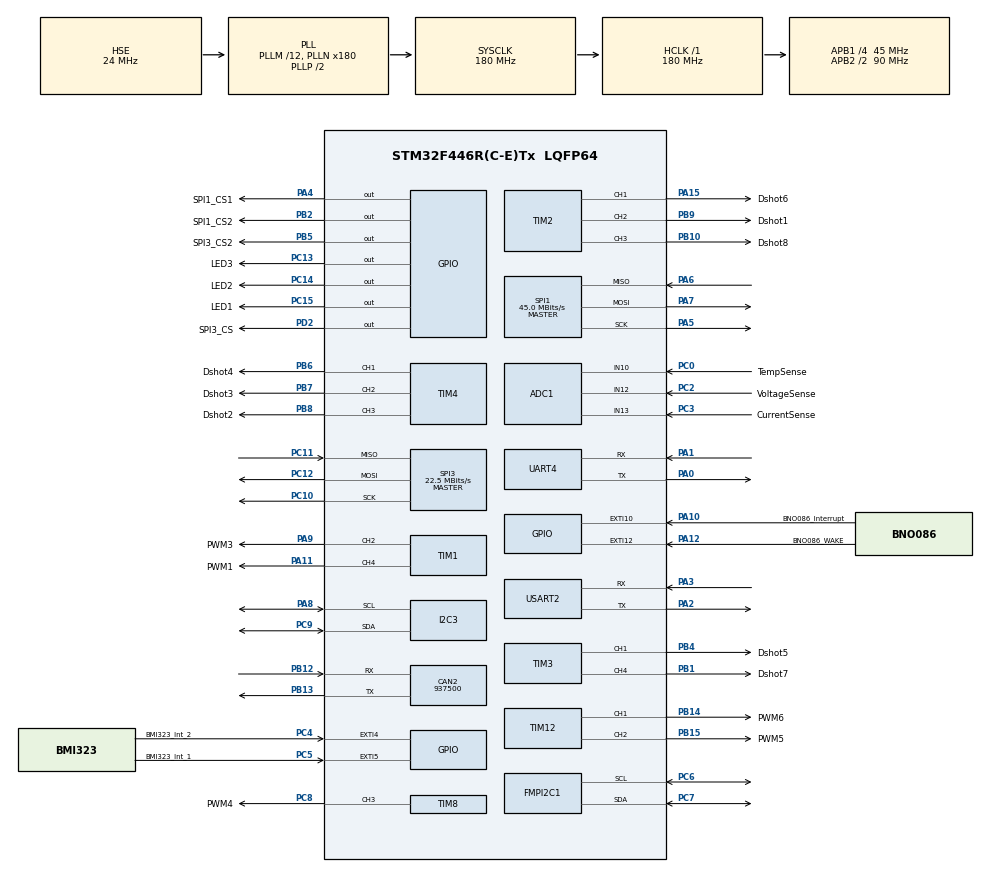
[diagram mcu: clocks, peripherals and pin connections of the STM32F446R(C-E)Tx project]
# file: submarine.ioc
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ADC1.Channel-0\#ChannelRegularConversion=ADC_CHANNEL_13
ADC1.Channel-1\#ChannelRegularConversion=ADC_CHANNEL_12
ADC1.Channel-2\#ChannelRegularConversion=ADC_CHANNEL_10
ADC1.ContinuousConvMode=ENABLE
ADC1.DMAContinuousRequests=ENABLE
ADC1.NbrOfConversion=3
ADC1.NbrOfConversionFlag=1
ADC1.Rank-0\#ChannelRegularConversion=1
ADC1.Rank-1\#ChannelRegularConversion=2
ADC1.Rank-2\#ChannelRegularConversion=3
ADC1.SamplingTime-0\#ChannelRegularConversion=ADC_SAMPLETIME_112CYCLES
ADC1.SamplingTime-1\#ChannelRegularConversion=ADC_SAMPLETIME_112CYCLES
ADC1.SamplingTime-2\#ChannelRegularConversion=ADC_SAMPLETIME_112CYCLES
ADC1.master=1
CAN2.BS1=CAN_BS1_1TQ
CAN2.BS2=CAN_BS2_1TQ
CAN2.CalculateBaudRate=937500
CAN2.CalculateTimeBit=1066
CAN2.CalculateTimeQuantum=355.55555555555554
Dma.ADC1.8.Direction=DMA_PERIPH_TO_MEMORY
Dma.ADC1.8.FIFOMode=DMA_FIFOMODE_DISABLE
Dma.ADC1.8.Instance=DMA2_Stream0
Dma.ADC1.8.MemDataAlignment=DMA_MDATAALIGN_HALFWORD
Dma.ADC1.8.MemInc=DMA_MINC_ENABLE
Dma.ADC1.8.Mode=DMA_CIRCULAR
Dma.ADC1.8.PeriphDataAlignment=DMA_PDATAALIGN_HALFWORD
Dma.ADC1.8.PeriphInc=DMA_PINC_DISABLE
Dma.ADC1.8.Priority=DMA_PRIORITY_LOW
Dma.Request0=TIM4_CH2
Dma.Request1=TIM2_CH1
Dma.Request2=TIM2_CH2/CH4
Dma.Request3=TIM3_CH1/TRIG
Dma.Request4=TIM3_CH4/UP
Dma.Request5=TIM2_UP/CH3
Dma.Request6=TIM4_CH3
Dma.Request7=TIM4_CH1
Dma.Request8=ADC1
Dma.TIM2_CH1.1.Direction=DMA_PERIPH_TO_MEMORY
Dma.TIM2_CH1.1.FIFOMode=DMA_FIFOMODE_DISABLE
Dma.TIM2_CH1.1.Instance=DMA1_Stream5
Dma.TIM2_CH1.1.MemDataAlignment=DMA_MDATAALIGN_WORD
Dma.TIM2_CH1.1.MemInc=DMA_MINC_ENABLE
Dma.TIM2_CH1.1.Mode=DMA_NORMAL
Dma.TIM2_CH1.1.PeriphDataAlignment=DMA_PDATAALIGN_WORD
Dma.TIM2_CH1.1.PeriphInc=DMA_PINC_DISABLE
Dma.TIM2_CH1.1.Priority=DMA_PRIORITY_LOW
Dma.TIM2_CH2/CH4.2.Direction=DMA_PERIPH_TO_MEMORY
Dma.TIM2_CH2/CH4.2.FIFOMode=DMA_FIFOMODE_DISABLE
Dma.TIM2_CH2/CH4.2.Instance=DMA1_Stream6
Dma.TIM2_CH2/CH4.2.MemDataAlignment=DMA_MDATAALIGN_WORD
Dma.TIM2_CH2/CH4.2.MemInc=DMA_MINC_ENABLE
Dma.TIM2_CH2/CH4.2.Mode=DMA_NORMAL
Dma.TIM2_CH2/CH4.2.PeriphDataAlignment=DMA_PDATAALIGN_WORD
Dma.TIM2_CH2/CH4.2.PeriphInc=DMA_PINC_DISABLE
Dma.TIM2_CH2/CH4.2.Priority=DMA_PRIORITY_LOW
Dma.TIM2_UP/CH3.5.Direction=DMA_PERIPH_TO_MEMORY
Dma.TIM2_UP/CH3.5.FIFOMode=DMA_FIFOMODE_DISABLE
Dma.TIM2_UP/CH3.5.Instance=DMA1_Stream1
Dma.TIM2_UP/CH3.5.MemDataAlignment=DMA_MDATAALIGN_WORD
Dma.TIM2_UP/CH3.5.MemInc=DMA_MINC_ENABLE
Dma.TIM2_UP/CH3.5.Mode=DMA_NORMAL
Dma.TIM2_UP/CH3.5.PeriphDataAlignment=DMA_PDATAALIGN_WORD
Dma.TIM2_UP/CH3.5.PeriphInc=DMA_PINC_DISABLE
Dma.TIM2_UP/CH3.5.Priority=DMA_PRIORITY_LOW
Dma.TIM3_CH1/TRIG.3.Direction=DMA_PERIPH_TO_MEMORY
Dma.TIM3_CH1/TRIG.3.FIFOMode=DMA_FIFOMODE_DISABLE
Dma.TIM3_CH1/TRIG.3.Instance=DMA1_Stream4
Dma.TIM3_CH1/TRIG.3.MemDataAlignment=DMA_MDATAALIGN_HALFWORD
Dma.TIM3_CH1/TRIG.3.MemInc=DMA_MINC_ENABLE
Dma.TIM3_CH1/TRIG.3.Mode=DMA_NORMAL
Dma.TIM3_CH1/TRIG.3.PeriphDataAlignment=DMA_PDATAALIGN_HALFWORD
Dma.TIM3_CH1/TRIG.3.PeriphInc=DMA_PINC_DISABLE
Dma.TIM3_CH1/TRIG.3.Priority=DMA_PRIORITY_LOW
Dma.TIM3_CH4/UP.4.Direction=DMA_PERIPH_TO_MEMORY
Dma.TIM3_CH4/UP.4.FIFOMode=DMA_FIFOMODE_DISABLE
Dma.TIM3_CH4/UP.4.Instance=DMA1_Stream2
Dma.TIM3_CH4/UP.4.MemDataAlignment=DMA_MDATAALIGN_HALFWORD
Dma.TIM3_CH4/UP.4.MemInc=DMA_MINC_ENABLE
Dma.TIM3_CH4/UP.4.Mode=DMA_NORMAL
Dma.TIM3_CH4/UP.4.PeriphDataAlignment=DMA_PDATAALIGN_HALFWORD
Dma.TIM3_CH4/UP.4.PeriphInc=DMA_PINC_DISABLE
Dma.TIM3_CH4/UP.4.Priority=DMA_PRIORITY_LOW
Dma.TIM4_CH1.7.Direction=DMA_PERIPH_TO_MEMORY
Dma.TIM4_CH1.7.FIFOMode=DMA_FIFOMODE_DISABLE
Dma.TIM4_CH1.7.Instance=DMA1_Stream0
Dma.TIM4_CH1.7.MemDataAlignment=DMA_MDATAALIGN_HALFWORD
Dma.TIM4_CH1.7.MemInc=DMA_MINC_ENABLE
Dma.TIM4_CH1.7.Mode=DMA_NORMAL
Dma.TIM4_CH1.7.PeriphDataAlignment=DMA_PDATAALIGN_HALFWORD
Dma.TIM4_CH1.7.PeriphInc=DMA_PINC_DISABLE
Dma.TIM4_CH1.7.Priority=DMA_PRIORITY_LOW
Dma.TIM4_CH2.0.Direction=DMA_PERIPH_TO_MEMORY
Dma.TIM4_CH2.0.FIFOMode=DMA_FIFOMODE_DISABLE
Dma.TIM4_CH2.0.Instance=DMA1_Stream3
Dma.TIM4_CH2.0.MemDataAlignment=DMA_MDATAALIGN_HALFWORD
Dma.TIM4_CH2.0.MemInc=DMA_MINC_ENABLE
Dma.TIM4_CH2.0.Mode=DMA_NORMAL
Dma.TIM4_CH2.0.PeriphDataAlignment=DMA_PDATAALIGN_HALFWORD
Dma.TIM4_CH2.0.PeriphInc=DMA_PINC_DISABLE
Dma.TIM4_CH2.0.Priority=DMA_PRIORITY_LOW
Dma.TIM4_CH3.6.Direction=DMA_PERIPH_TO_MEMORY
Dma.TIM4_CH3.6.FIFOMode=DMA_FIFOMODE_DISABLE
Dma.TIM4_CH3.6.Instance=DMA1_Stream7
Dma.TIM4_CH3.6.MemDataAlignment=DMA_MDATAALIGN_HALFWORD
Dma.TIM4_CH3.6.MemInc=DMA_MINC_ENABLE
Dma.TIM4_CH3.6.Mode=DMA_NORMAL
Dma.TIM4_CH3.6.PeriphDataAlignment=DMA_PDATAALIGN_HALFWORD
Dma.TIM4_CH3.6.PeriphInc=DMA_PINC_DISABLE
Dma.TIM4_CH3.6.Priority=DMA_PRIORITY_LOW
FMPI2C1.Timeout=0x00008225
FMPI2C1.Timing=0xC0000E12
Mcu.Family=STM32F4
Mcu.Name=STM32F446R(C-E)Tx
Mcu.Package=LQFP64
NVIC.ADC_IRQn=true\:0\:0\:false\:false\:true\:true\:true\:true
NVIC.DMA1_Stream0_IRQn=true\:0\:0\:false\:false\:true\:false\:true\:true
NVIC.DMA1_Stream1_IRQn=true\:0\:0\:false\:false\:true\:false\:true\:true
NVIC.DMA1_Stream2_IRQn=true\:0\:0\:false\:false\:true\:false\:true\:true
NVIC.DMA1_Stream3_IRQn=true\:0\:0\:false\:false\:true\:false\:true\:true
NVIC.DMA1_Stream4_IRQn=true\:0\:0\:false\:false\:true\:false\:true\:true
NVIC.DMA1_Stream5_IRQn=true\:0\:0\:false\:false\:true\:false\:true\:true
NVIC.DMA1_Stream6_IRQn=true\:0\:0\:false\:false\:true\:false\:true\:true
NVIC.DMA1_Stream7_IRQn=true\:0\:0\:false\:false\:true\:false\:true\:true
NVIC.DMA2_Stream0_IRQn=true\:0\:0\:false\:false\:true\:false\:true\:true
NVIC.PriorityGroup=NVIC_PRIORITYGROUP_4
PA0-WKUP.Mode=Asynchronous
PA0-WKUP.Signal=UART4_TX
PA1.Mode=Asynchronous
PA1.Signal=UART4_RX
PA10.GPIO_Label=BNO086_Interrupt
PA10.Signal=GPXTI10
PA11.GPIO_Label=PWM1
PA11.Signal=S_TIM1_CH4
PA12.GPIO_Label=BNO086_WAKE
PA12.Signal=GPXTI12
PA13.Mode=Trace_Asynchronous_SW
PA13.Signal=SYS_JTMS-SWDIO
PA14.Mode=Trace_Asynchronous_SW
PA14.Signal=SYS_JTCK-SWCLK
PA15.GPIO_Label=Dshot6
PA15.Signal=S_TIM2_CH1_ETR
PA2.Mode=Asynchronous
PA2.Signal=USART2_TX
PA3.Mode=Asynchronous
PA3.Signal=USART2_RX
PA4.GPIO_Label=SPI1_CS1
PA4.Signal=GPIO_Output
PA5.Mode=Full_Duplex_Master
PA5.Signal=SPI1_SCK
PA6.Mode=Full_Duplex_Master
PA6.Signal=SPI1_MISO
PA7.Mode=Full_Duplex_Master
PA7.Signal=SPI1_MOSI
PA8.Mode=I2C
PA8.Signal=I2C3_SCL
PA9.GPIO_Label=PWM3
PA9.Signal=S_TIM1_CH2
PB1.GPIO_Label=Dshot7
PB1.Signal=S_TIM3_CH4
PB10.GPIO_Label=Dshot8
PB10.Signal=S_TIM2_CH3
PB12.Mode=CAN_Activate
PB12.Signal=CAN2_RX
PB13.Mode=CAN_Activate
PB13.Signal=CAN2_TX
PB14.GPIO_Label=PWM6
PB14.Signal=S_TIM12_CH1
PB15.GPIO_Label=PWM5
PB15.Signal=S_TIM12_CH2
PB2.GPIO_Label=SPI1_CS2
PB2.Signal=GPIO_Output
PB3.Mode=Trace_Asynchronous_SW
PB3.Signal=SYS_JTDO-SWO
PB4.GPIO_Label=Dshot5
PB4.Signal=S_TIM3_CH1
PB5.GPIO_Label=SPI3_CS2
PB5.Signal=GPIO_Output
PB6.GPIO_Label=Dshot4
PB6.Signal=S_TIM4_CH1
PB7.GPIO_Label=Dshot3
PB7.Signal=S_TIM4_CH2
PB8.GPIO_Label=Dshot2
PB8.Signal=S_TIM4_CH3
PB9.GPIO_Label=Dshot1
PB9.Signal=S_TIM2_CH2
PC0.GPIO_Label=TempSense
PC0.Signal=ADCx_IN10
PC10.Mode=Full_Duplex_Master
PC10.Signal=SPI3_SCK
PC11.Mode=Full_Duplex_Master
PC11.Signal=SPI3_MISO
PC12.Mode=Full_Duplex_Master
PC12.Signal=SPI3_MOSI
PC13.GPIO_Label=LED3
PC13.PinState=GPIO_PIN_SET
PC13.Signal=GPIO_Output
PC14-OSC32_IN.GPIO_Label=LED2
PC14-OSC32_IN.PinState=GPIO_PIN_SET
PC14-OSC32_IN.Signal=GPIO_Output
PC15-OSC32_OUT.GPIO_Label=LED1
PC15-OSC32_OUT.PinState=GPIO_PIN_SET
PC15-OSC32_OUT.Signal=GPIO_Output
PC2.GPIO_Label=VoltageSense
PC2.Signal=ADCx_IN12
PC3.GPIO_Label=CurrentSense
PC3.Signal=ADCx_IN13
PC4.GPIO_Label=BMI323_Int_2
PC4.Signal=GPXTI4
PC5.GPIO_Label=BMI323_Int_1
PC5.Signal=GPXTI5
PC6.Mode=I2C
PC6.Signal=FMPI2C1_SCL
PC7.Mode=I2C
PC7.Signal=FMPI2C1_SDA
PC8.GPIO_Label=PWM4
PC8.Signal=S_TIM8_CH3
PC9.Mode=I2C
PC9.Signal=I2C3_SDA
PD2.GPIO_Label=SPI3_CS
PD2.Signal=GPIO_Output
PH0-OSC_IN.Mode=HSE-External-Oscillator
PH0-OSC_IN.Signal=RCC_OSC_IN
PH1-OSC_OUT.Mode=HSE-External-Oscillator
PH1-OSC_OUT.Signal=RCC_OSC_OUT
ProjectManager.HeapSize=0x200
ProjectManager.StackSize=0x400
ProjectManager.TargetToolchain=STM32CubeIDE
RCC.AHBFreq_Value=180000000
RCC.APB1CLKDivider=RCC_HCLK_DIV4
RCC.APB1Freq_Value=45000000
RCC.APB1TimFreq_Value=90000000
RCC.APB2CLKDivider=RCC_HCLK_DIV2
RCC.APB2Freq_Value=90000000
RCC.APB2TimFreq_Value=180000000
RCC.CortexFreq_Value=180000000
RCC.HCLKFreq_Value=180000000
RCC.HSE_VALUE=24000000
RCC.PLLM=12
RCC.PLLN=180
RCC.PLLSAIM=12
RCC.PLLSAIN=96
RCC.PLLSAIP=RCC_PLLSAIP_DIV4
RCC.PLLSourceVirtual=RCC_PLLSOURCE_HSE
RCC.SYSCLKFreq_VALUE=180000000
RCC.SYSCLKSource=RCC_SYSCLKSOURCE_PLLCLK
RCC.USBCLockSelection=RCC_CLK48CLKSOURCE_PLLSAIP
RCC.USBFreq_Value=48000000
RCC.VCOOutputFreq_Value=360000000
SH.ADCx_IN10.0=ADC1_IN10,IN10
SH.ADCx_IN12.0=ADC1_IN12,IN12
SH.ADCx_IN13.0=ADC1_IN13,IN13
SH.S_TIM12_CH1.0=TIM12_CH1,PWM Generation1 CH1
SH.S_TIM12_CH2.0=TIM12_CH2,PWM Generation2 CH2
SH.S_TIM1_CH2.0=TIM1_CH2,PWM Generation2 CH2
SH.S_TIM1_CH4.0=TIM1_CH4,PWM Generation4 CH4
SH.S_TIM2_CH1_ETR.0=TIM2_CH1,PWM Generation1 CH1
SH.S_TIM2_CH2.0=TIM2_CH2,PWM Generation2 CH2
SH.S_TIM2_CH3.0=TIM2_CH3,PWM Generation3 CH3
SH.S_TIM3_CH1.0=TIM3_CH1,PWM Generation1 CH1
SH.S_TIM3_CH4.0=TIM3_CH4,PWM Generation4 CH4
SH.S_TIM4_CH1.0=TIM4_CH1,PWM Generation1 CH1
SH.S_TIM4_CH2.0=TIM4_CH2,PWM Generation2 CH2
SH.S_TIM4_CH3.0=TIM4_CH3,PWM Generation3 CH3
SH.S_TIM8_CH3.0=TIM8_CH3,PWM Generation3 CH3
SPI1.BaudRatePrescaler=SPI_BAUDRATEPRESCALER_2
SPI1.CalculateBaudRate=45.0 MBits/s
SPI1.Direction=SPI_DIRECTION_2LINES
SPI1.Mode=SPI_MODE_MASTER
SPI1.VirtualType=VM_MASTER
SPI3.BaudRatePrescaler=SPI_BAUDRATEPRESCALER_2
SPI3.CalculateBaudRate=22.5 MBits/s
SPI3.Direction=SPI_DIRECTION_2LINES
SPI3.Mode=SPI_MODE_MASTER
SPI3.VirtualType=VM_MASTER
TIM1.Channel-PWM\ Generation2\ CH2=TIM_CHANNEL_2
TIM1.Channel-PWM\ Generation4\ CH4=TIM_CHANNEL_4
TIM12.Channel-PWM\ Generation1\ CH1=TIM_CHANNEL_1
TIM12.Channel-PWM\ Generation2\ CH2=TIM_CHANNEL_2
TIM2.Channel-PWM\ Generation1\ CH1=TIM_CHANNEL_1
TIM2.Channel-PWM\ Generation2\ CH2=TIM_CHANNEL_2
TIM2.Channel-PWM\ Generation3\ CH3=TIM_CHANNEL_3
TIM3.Channel-PWM\ Generation1\ CH1=TIM_CHANNEL_1
TIM3.Channel-PWM\ Generation4\ CH4=TIM_CHANNEL_4
TIM4.Channel-PWM\ Generation1\ CH1=TIM_CHANNEL_1
TIM4.Channel-PWM\ Generation2\ CH2=TIM_CHANNEL_2
TIM4.Channel-PWM\ Generation3\ CH3=TIM_CHANNEL_3
TIM8.Channel-PWM\ Generation3\ CH3=TIM_CHANNEL_3
UART4.VirtualMode=Asynchronous
USART2.VirtualMode=VM_ASYNC
board=custom

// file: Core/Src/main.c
/* USER CODE BEGIN Header */
/**
  ******************************************************************************
  * @file           : main.c
  * @brief          : Main program body
  ******************************************************************************
  * @attention
  *
  * Copyright (c) 2026 STMicroelectronics.
  * All rights reserved.
  *
  * This software is licensed under terms that can be found in the LICENSE file
  * in the root directory of this software component.
  * If no LICENSE file comes with this software, it is provided AS-IS.
  *
  ******************************************************************************
  */
/* USER CODE END Header */
#include "main.h"

ADC_HandleTypeDef hadc1;
DMA_HandleTypeDef hdma_adc1;

CAN_HandleTypeDef hcan2;

FMPI2C_HandleTypeDef hfmpi2c1;

I2C_HandleTypeDef hi2c3;

SPI_HandleTypeDef hspi1;
SPI_HandleTypeDef hspi3;

TIM_HandleTypeDef htim1;
TIM_HandleTypeDef htim2;
TIM_HandleTypeDef htim3;
TIM_HandleTypeDef htim4;
TIM_HandleTypeDef htim8;
TIM_HandleTypeDef htim12;
DMA_HandleTypeDef hdma_tim2_ch1;
DMA_HandleTypeDef hdma_tim2_ch2_ch4;
DMA_HandleTypeDef hdma_tim2_up_ch3;
DMA_HandleTypeDef hdma_tim3_ch1_trig;
DMA_HandleTypeDef hdma_tim3_ch4_up;
DMA_HandleTypeDef hdma_tim4_ch2;
DMA_HandleTypeDef hdma_tim4_ch3;
DMA_HandleTypeDef hdma_tim4_ch1;

UART_HandleTypeDef huart4;
UART_HandleTypeDef huart2;

void SystemClock_Config(void);
static void MX_GPIO_Init(void);
static void MX_DMA_Init(void);
static void MX_SPI1_Init(void);
static void MX_SPI3_Init(void);
static void MX_UART4_Init(void);
static void MX_USART2_UART_Init(void);
static void MX_TIM2_Init(void);
static void MX_TIM3_Init(void);
static void MX_TIM4_Init(void);
static void MX_CAN2_Init(void);
static void MX_FMPI2C1_Init(void);
static void MX_I2C3_Init(void);
static void MX_TIM1_Init(void);
static void MX_TIM8_Init(void);
static void MX_TIM12_Init(void);
static void MX_ADC1_Init(void);

/* USER CODE BEGIN 0 */

uint16_t adcBuffer[3];

uint16_t currentSenseRaw, voltageSenseRaw, tempSenseRaw;

float currentSense, voltageSense, tempSense;

const float currentSenseScale = 3.3 / (1 << 12) / 200 / 0.0003 * (4.99 / 8.6); // (4.99 / 8.6) correction value because it wasn't cooperating

float currentFiltered = 0;
/* USER CODE END 0 */

int main(void)
{

  /* MCU Configuration--------------------------------------------------------*/

  /* Reset of all peripherals, Initializes the Flash interface and the Systick. */
  HAL_Init();

  /* Configure the system clock */
  SystemClock_Config();

  /* Initialize all configured peripherals */
  MX_GPIO_Init();
  MX_DMA_Init();
  MX_SPI1_Init();
  MX_SPI3_Init();
  MX_UART4_Init();
  MX_USART2_UART_Init();
  MX_TIM2_Init();
  MX_TIM3_Init();
  MX_TIM4_Init();
  MX_CAN2_Init();
  MX_FMPI2C1_Init();
  MX_I2C3_Init();
  MX_TIM1_Init();
  MX_TIM8_Init();
  MX_TIM12_Init();
  MX_ADC1_Init();
  /* USER CODE BEGIN 2 */

	HAL_ADC_Start_DMA(&hadc1, (uint32_t*) &adcBuffer, 3);

  /* USER CODE END 2 */

  /* Infinite loop */
  /* USER CODE BEGIN WHILE */
  while (1)
  {

		currentSenseRaw = adcBuffer[0];
		currentSense = currentSenseRaw * currentSenseScale;

		currentFiltered = currentFiltered * 0.99 + currentSense * 0.01;
//		HAL_GPIO_TogglePin(LED1_GPIO_Port, LED1_Pin);

//		HAL_Delay(420);
    /* USER CODE END WHILE */

  }
}

void SystemClock_Config(void)
{
  RCC_OscInitTypeDef RCC_OscInitStruct = {0};
  RCC_ClkInitTypeDef RCC_ClkInitStruct = {0};

  /** Configure the main internal regulator output voltage
  */
  __HAL_RCC_PWR_CLK_ENABLE();
  __HAL_PWR_VOLTAGESCALING_CONFIG(PWR_REGULATOR_VOLTAGE_SCALE1);

  /** Initializes the RCC Oscillators according to the specified parameters
  * in the RCC_OscInitTypeDef structure.
  */
  RCC_OscInitStruct.OscillatorType = RCC_OSCILLATORTYPE_HSE;
  RCC_OscInitStruct.HSEState = RCC_HSE_ON;
  RCC_OscInitStruct.PLL.PLLState = RCC_PLL_ON;
  RCC_OscInitStruct.PLL.PLLSource = RCC_PLLSOURCE_HSE;
  RCC_OscInitStruct.PLL.PLLM = 12;
  RCC_OscInitStruct.PLL.PLLN = 180;
  RCC_OscInitStruct.PLL.PLLP = RCC_PLLP_DIV2;
  RCC_OscInitStruct.PLL.PLLQ = 2;
  RCC_OscInitStruct.PLL.PLLR = 2;
  if (HAL_RCC_OscConfig(&RCC_OscInitStruct) != HAL_OK)
  {
    Error_Handler();
  }

  /** Activate the Over-Drive mode
  */
  if (HAL_PWREx_EnableOverDrive() != HAL_OK)
  {
    Error_Handler();
  }

  /** Initializes the CPU, AHB and APB buses clocks
  */
  RCC_ClkInitStruct.ClockType = RCC_CLOCKTYPE_HCLK|RCC_CLOCKTYPE_SYSCLK
                              |RCC_CLOCKTYPE_PCLK1|RCC_CLOCKTYPE_PCLK2;
  RCC_ClkInitStruct.SYSCLKSource = RCC_SYSCLKSOURCE_PLLCLK;
  RCC_ClkInitStruct.AHBCLKDivider = RCC_SYSCLK_DIV1;
  RCC_ClkInitStruct.APB1CLKDivider = RCC_HCLK_DIV4;
  RCC_ClkInitStruct.APB2CLKDivider = RCC_HCLK_DIV2;

  if (HAL_RCC_ClockConfig(&RCC_ClkInitStruct, FLASH_LATENCY_5) != HAL_OK)
  {
    Error_Handler();
  }
}

static void MX_ADC1_Init(void)
{

  ADC_ChannelConfTypeDef sConfig = {0};

  /** Configure the global features of the ADC (Clock, Resolution, Data Alignment and number of conversion)
  */
  hadc1.Instance = ADC1;
  hadc1.Init.ClockPrescaler = ADC_CLOCK_SYNC_PCLK_DIV4;
  hadc1.Init.Resolution = ADC_RESOLUTION_12B;
  hadc1.Init.ScanConvMode = ENABLE;
  hadc1.Init.ContinuousConvMode = ENABLE;
  hadc1.Init.DiscontinuousConvMode = DISABLE;
  hadc1.Init.ExternalTrigConvEdge = ADC_EXTERNALTRIGCONVEDGE_NONE;
  hadc1.Init.ExternalTrigConv = ADC_SOFTWARE_START;
  hadc1.Init.DataAlign = ADC_DATAALIGN_RIGHT;
  hadc1.Init.NbrOfConversion = 3;
  hadc1.Init.DMAContinuousRequests = ENABLE;
  hadc1.Init.EOCSelection = ADC_EOC_SINGLE_CONV;
  if (HAL_ADC_Init(&hadc1) != HAL_OK)
  {
    Error_Handler();
  }

  /** Configure for the selected ADC regular channel its corresponding rank in the sequencer and its sample time.
  */
  sConfig.Channel = ADC_CHANNEL_13;
  sConfig.Rank = 1;
  sConfig.SamplingTime = ADC_SAMPLETIME_112CYCLES;
  if (HAL_ADC_ConfigChannel(&hadc1, &sConfig) != HAL_OK)
  {
    Error_Handler();
  }

  /** Configure for the selected ADC regular channel its corresponding rank in the sequencer and its sample time.
  */
  sConfig.Channel = ADC_CHANNEL_12;
  sConfig.Rank = 2;
  if (HAL_ADC_ConfigChannel(&hadc1, &sConfig) != HAL_OK)
  {
    Error_Handler();
  }

  /** Configure for the selected ADC regular channel its corresponding rank in the sequencer and its sample time.
  */
  sConfig.Channel = ADC_CHANNEL_10;
  sConfig.Rank = 3;
  if (HAL_ADC_ConfigChannel(&hadc1, &sConfig) != HAL_OK)
  {
    Error_Handler();
  }

}

static void MX_CAN2_Init(void)
{

  hcan2.Instance = CAN2;
  hcan2.Init.Prescaler = 16;
  hcan2.Init.Mode = CAN_MODE_NORMAL;
  hcan2.Init.SyncJumpWidth = CAN_SJW_1TQ;
  hcan2.Init.TimeSeg1 = CAN_BS1_1TQ;
  hcan2.Init.TimeSeg2 = CAN_BS2_1TQ;
  hcan2.Init.TimeTriggeredMode = DISABLE;
  hcan2.Init.AutoBusOff = DISABLE;
  hcan2.Init.AutoWakeUp = DISABLE;
  hcan2.Init.AutoRetransmission = DISABLE;
  hcan2.Init.ReceiveFifoLocked = DISABLE;
  hcan2.Init.TransmitFifoPriority = DISABLE;
  if (HAL_CAN_Init(&hcan2) != HAL_OK)
  {
    Error_Handler();
  }

}

static void MX_FMPI2C1_Init(void)
{

  hfmpi2c1.Instance = FMPI2C1;
  hfmpi2c1.Init.Timing = 0xC0000E12;
  hfmpi2c1.Init.OwnAddress1 = 0;
  hfmpi2c1.Init.AddressingMode = FMPI2C_ADDRESSINGMODE_7BIT;
  hfmpi2c1.Init.DualAddressMode = FMPI2C_DUALADDRESS_DISABLE;
  hfmpi2c1.Init.OwnAddress2 = 0;
  hfmpi2c1.Init.OwnAddress2Masks = FMPI2C_OA2_NOMASK;
  hfmpi2c1.Init.GeneralCallMode = FMPI2C_GENERALCALL_DISABLE;
  hfmpi2c1.Init.NoStretchMode = FMPI2C_NOSTRETCH_DISABLE;
  if (HAL_FMPI2C_Init(&hfmpi2c1) != HAL_OK)
  {
    Error_Handler();
  }

  /** Configure Analogue filter
  */
  if (HAL_FMPI2CEx_ConfigAnalogFilter(&hfmpi2c1, FMPI2C_ANALOGFILTER_ENABLE) != HAL_OK)
  {
    Error_Handler();
  }

}

static void MX_I2C3_Init(void)
{

  hi2c3.Instance = I2C3;
  hi2c3.Init.ClockSpeed = 100000;
  hi2c3.Init.DutyCycle = I2C_DUTYCYCLE_2;
  hi2c3.Init.OwnAddress1 = 0;
  hi2c3.Init.AddressingMode = I2C_ADDRESSINGMODE_7BIT;
  hi2c3.Init.DualAddressMode = I2C_DUALADDRESS_DISABLE;
  hi2c3.Init.OwnAddress2 = 0;
  hi2c3.Init.GeneralCallMode = I2C_GENERALCALL_DISABLE;
  hi2c3.Init.NoStretchMode = I2C_NOSTRETCH_DISABLE;
  if (HAL_I2C_Init(&hi2c3) != HAL_OK)
  {
    Error_Handler();
  }

}

static void MX_SPI1_Init(void)
{

  /* SPI1 parameter configuration*/
  hspi1.Instance = SPI1;
  hspi1.Init.Mode = SPI_MODE_MASTER;
  hspi1.Init.Direction = SPI_DIRECTION_2LINES;
  hspi1.Init.DataSize = SPI_DATASIZE_8BIT;
  hspi1.Init.CLKPolarity = SPI_POLARITY_LOW;
  hspi1.Init.CLKPhase = SPI_PHASE_1EDGE;
  hspi1.Init.NSS = SPI_NSS_SOFT;
  hspi1.Init.BaudRatePrescaler = SPI_BAUDRATEPRESCALER_2;
  hspi1.Init.FirstBit = SPI_FIRSTBIT_MSB;
  hspi1.Init.TIMode = SPI_TIMODE_DISABLE;
  hspi1.Init.CRCCalculation = SPI_CRCCALCULATION_DISABLE;
  hspi1.Init.CRCPolynomial = 10;
  if (HAL_SPI_Init(&hspi1) != HAL_OK)
  {
    Error_Handler();
  }

}

static void MX_SPI3_Init(void)
{

  /* SPI3 parameter configuration*/
  hspi3.Instance = SPI3;
  hspi3.Init.Mode = SPI_MODE_MASTER;
  hspi3.Init.Direction = SPI_DIRECTION_2LINES;
  hspi3.Init.DataSize = SPI_DATASIZE_8BIT;
  hspi3.Init.CLKPolarity = SPI_POLARITY_LOW;
  hspi3.Init.CLKPhase = SPI_PHASE_1EDGE;
  hspi3.Init.NSS = SPI_NSS_SOFT;
  hspi3.Init.BaudRatePrescaler = SPI_BAUDRATEPRESCALER_2;
  hspi3.Init.FirstBit = SPI_FIRSTBIT_MSB;
  hspi3.Init.TIMode = SPI_TIMODE_DISABLE;
  hspi3.Init.CRCCalculation = SPI_CRCCALCULATION_DISABLE;
  hspi3.Init.CRCPolynomial = 10;
  if (HAL_SPI_Init(&hspi3) != HAL_OK)
  {
    Error_Handler();
  }

}

static void MX_TIM1_Init(void)
{

  TIM_MasterConfigTypeDef sMasterConfig = {0};
  TIM_OC_InitTypeDef sConfigOC = {0};
  TIM_BreakDeadTimeConfigTypeDef sBreakDeadTimeConfig = {0};

  htim1.Instance = TIM1;
  htim1.Init.Prescaler = 0;
  htim1.Init.CounterMode = TIM_COUNTERMODE_UP;
  htim1.Init.Period = 65535;
  htim1.Init.ClockDivision = TIM_CLOCKDIVISION_DIV1;
  htim1.Init.RepetitionCounter = 0;
  htim1.Init.AutoReloadPreload = TIM_AUTORELOAD_PRELOAD_DISABLE;
  if (HAL_TIM_PWM_Init(&htim1) != HAL_OK)
  {
    Error_Handler();
  }
  sMasterConfig.MasterOutputTrigger = TIM_TRGO_RESET;
  sMasterConfig.MasterSlaveMode = TIM_MASTERSLAVEMODE_DISABLE;
  if (HAL_TIMEx_MasterConfigSynchronization(&htim1, &sMasterConfig) != HAL_OK)
  {
    Error_Handler();
  }
  sConfigOC.OCMode = TIM_OCMODE_PWM1;
  sConfigOC.Pulse = 0;
  sConfigOC.OCPolarity = TIM_OCPOLARITY_HIGH;
  sConfigOC.OCNPolarity = TIM_OCNPOLARITY_HIGH;
  sConfigOC.OCFastMode = TIM_OCFAST_DISABLE;
  sConfigOC.OCIdleState = TIM_OCIDLESTATE_RESET;
  sConfigOC.OCNIdleState = TIM_OCNIDLESTATE_RESET;
  if (HAL_TIM_PWM_ConfigChannel(&htim1, &sConfigOC, TIM_CHANNEL_2) != HAL_OK)
  {
    Error_Handler();
  }
  if (HAL_TIM_PWM_ConfigChannel(&htim1, &sConfigOC, TIM_CHANNEL_4) != HAL_OK)
  {
    Error_Handler();
  }
  sBreakDeadTimeConfig.OffStateRunMode = TIM_OSSR_DISABLE;
  sBreakDeadTimeConfig.OffStateIDLEMode = TIM_OSSI_DISABLE;
  sBreakDeadTimeConfig.LockLevel = TIM_LOCKLEVEL_OFF;
  sBreakDeadTimeConfig.DeadTime = 0;
  sBreakDeadTimeConfig.BreakState = TIM_BREAK_DISABLE;
  sBreakDeadTimeConfig.BreakPolarity = TIM_BREAKPOLARITY_HIGH;
  sBreakDeadTimeConfig.AutomaticOutput = TIM_AUTOMATICOUTPUT_DISABLE;
  if (HAL_TIMEx_ConfigBreakDeadTime(&htim1, &sBreakDeadTimeConfig) != HAL_OK)
  {
    Error_Handler();
  }
  HAL_TIM_MspPostInit(&htim1);

}

static void MX_TIM2_Init(void)
{

  TIM_MasterConfigTypeDef sMasterConfig = {0};
  TIM_OC_InitTypeDef sConfigOC = {0};

  htim2.Instance = TIM2;
  htim2.Init.Prescaler = 0;
  htim2.Init.CounterMode = TIM_COUNTERMODE_UP;
  htim2.Init.Period = 4294967295;
  htim2.Init.ClockDivision = TIM_CLOCKDIVISION_DIV1;
  htim2.Init.AutoReloadPreload = TIM_AUTORELOAD_PRELOAD_DISABLE;
  if (HAL_TIM_PWM_Init(&htim2) != HAL_OK)
  {
    Error_Handler();
  }
  sMasterConfig.MasterOutputTrigger = TIM_TRGO_RESET;
  sMasterConfig.MasterSlaveMode = TIM_MASTERSLAVEMODE_DISABLE;
  if (HAL_TIMEx_MasterConfigSynchronization(&htim2, &sMasterConfig) != HAL_OK)
  {
    Error_Handler();
  }
  sConfigOC.OCMode = TIM_OCMODE_PWM1;
  sConfigOC.Pulse = 0;
  sConfigOC.OCPolarity = TIM_OCPOLARITY_HIGH;
  sConfigOC.OCFastMode = TIM_OCFAST_DISABLE;
  if (HAL_TIM_PWM_ConfigChannel(&htim2, &sConfigOC, TIM_CHANNEL_1) != HAL_OK)
  {
    Error_Handler();
  }
  if (HAL_TIM_PWM_ConfigChannel(&htim2, &sConfigOC, TIM_CHANNEL_2) != HAL_OK)
  {
    Error_Handler();
  }
  if (HAL_TIM_PWM_ConfigChannel(&htim2, &sConfigOC, TIM_CHANNEL_3) != HAL_OK)
  {
    Error_Handler();
  }
  HAL_TIM_MspPostInit(&htim2);

}

static void MX_TIM3_Init(void)
{

  TIM_MasterConfigTypeDef sMasterConfig = {0};
  TIM_OC_InitTypeDef sConfigOC = {0};

  htim3.Instance = TIM3;
  htim3.Init.Prescaler = 0;
  htim3.Init.CounterMode = TIM_COUNTERMODE_UP;
  htim3.Init.Period = 65535;
  htim3.Init.ClockDivision = TIM_CLOCKDIVISION_DIV1;
  htim3.Init.AutoReloadPreload = TIM_AUTORELOAD_PRELOAD_DISABLE;
  if (HAL_TIM_PWM_Init(&htim3) != HAL_OK)
  {
    Error_Handler();
  }
  sMasterConfig.MasterOutputTrigger = TIM_TRGO_RESET;
  sMasterConfig.MasterSlaveMode = TIM_MASTERSLAVEMODE_DISABLE;
  if (HAL_TIMEx_MasterConfigSynchronization(&htim3, &sMasterConfig) != HAL_OK)
  {
    Error_Handler();
  }
  sConfigOC.OCMode = TIM_OCMODE_PWM1;
  sConfigOC.Pulse = 0;
  sConfigOC.OCPolarity = TIM_OCPOLARITY_HIGH;
  sConfigOC.OCFastMode = TIM_OCFAST_DISABLE;
  if (HAL_TIM_PWM_ConfigChannel(&htim3, &sConfigOC, TIM_CHANNEL_1) != HAL_OK)
  {
    Error_Handler();
  }
  if (HAL_TIM_PWM_ConfigChannel(&htim3, &sConfigOC, TIM_CHANNEL_4) != HAL_OK)
  {
    Error_Handler();
  }
  HAL_TIM_MspPostInit(&htim3);

}

static void MX_TIM4_Init(void)
{

  TIM_MasterConfigTypeDef sMasterConfig = {0};
  TIM_OC_InitTypeDef sConfigOC = {0};

  htim4.Instance = TIM4;
  htim4.Init.Prescaler = 0;
  htim4.Init.CounterMode = TIM_COUNTERMODE_UP;
  htim4.Init.Period = 65535;
  htim4.Init.ClockDivision = TIM_CLOCKDIVISION_DIV1;
  htim4.Init.AutoReloadPreload = TIM_AUTORELOAD_PRELOAD_DISABLE;
  if (HAL_TIM_PWM_Init(&htim4) != HAL_OK)
  {
    Error_Handler();
  }
  sMasterConfig.MasterOutputTrigger = TIM_TRGO_RESET;
  sMasterConfig.MasterSlaveMode = TIM_MASTERSLAVEMODE_DISABLE;
  if (HAL_TIMEx_MasterConfigSynchronization(&htim4, &sMasterConfig) != HAL_OK)
  {
    Error_Handler();
  }
  sConfigOC.OCMode = TIM_OCMODE_PWM1;
  sConfigOC.Pulse = 0;
  sConfigOC.OCPolarity = TIM_OCPOLARITY_HIGH;
  sConfigOC.OCFastMode = TIM_OCFAST_DISABLE;
  if (HAL_TIM_PWM_ConfigChannel(&htim4, &sConfigOC, TIM_CHANNEL_1) != HAL_OK)
  {
    Error_Handler();
  }
  if (HAL_TIM_PWM_ConfigChannel(&htim4, &sConfigOC, TIM_CHANNEL_2) != HAL_OK)
  {
    Error_Handler();
  }
  if (HAL_TIM_PWM_ConfigChannel(&htim4, &sConfigOC, TIM_CHANNEL_3) != HAL_OK)
  {
    Error_Handler();
  }
  HAL_TIM_MspPostInit(&htim4);

}

static void MX_TIM8_Init(void)
{

  TIM_MasterConfigTypeDef sMasterConfig = {0};
  TIM_OC_InitTypeDef sConfigOC = {0};
  TIM_BreakDeadTimeConfigTypeDef sBreakDeadTimeConfig = {0};

  htim8.Instance = TIM8;
  htim8.Init.Prescaler = 0;
  htim8.Init.CounterMode = TIM_COUNTERMODE_UP;
  htim8.Init.Period = 65535;
  htim8.Init.ClockDivision = TIM_CLOCKDIVISION_DIV1;
  htim8.Init.RepetitionCounter = 0;
  htim8.Init.AutoReloadPreload = TIM_AUTORELOAD_PRELOAD_DISABLE;
  if (HAL_TIM_PWM_Init(&htim8) != HAL_OK)
  {
    Error_Handler();
  }
  sMasterConfig.MasterOutputTrigger = TIM_TRGO_RESET;
  sMasterConfig.MasterSlaveMode = TIM_MASTERSLAVEMODE_DISABLE;
  if (HAL_TIMEx_MasterConfigSynchronization(&htim8, &sMasterConfig) != HAL_OK)
  {
    Error_Handler();
  }
  sConfigOC.OCMode = TIM_OCMODE_PWM1;
  sConfigOC.Pulse = 0;
  sConfigOC.OCPolarity = TIM_OCPOLARITY_HIGH;
  sConfigOC.OCNPolarity = TIM_OCNPOLARITY_HIGH;
  sConfigOC.OCFastMode = TIM_OCFAST_DISABLE;
  sConfigOC.OCIdleState = TIM_OCIDLESTATE_RESET;
  sConfigOC.OCNIdleState = TIM_OCNIDLESTATE_RESET;
  if (HAL_TIM_PWM_ConfigChannel(&htim8, &sConfigOC, TIM_CHANNEL_3) != HAL_OK)
  {
    Error_Handler();
  }
  sBreakDeadTimeConfig.OffStateRunMode = TIM_OSSR_DISABLE;
  sBreakDeadTimeConfig.OffStateIDLEMode = TIM_OSSI_DISABLE;
  sBreakDeadTimeConfig.LockLevel = TIM_LOCKLEVEL_OFF;
  sBreakDeadTimeConfig.DeadTime = 0;
  sBreakDeadTimeConfig.BreakState = TIM_BREAK_DISABLE;
  sBreakDeadTimeConfig.BreakPolarity = TIM_BREAKPOLARITY_HIGH;
  sBreakDeadTimeConfig.AutomaticOutput = TIM_AUTOMATICOUTPUT_DISABLE;
  if (HAL_TIMEx_ConfigBreakDeadTime(&htim8, &sBreakDeadTimeConfig) != HAL_OK)
  {
    Error_Handler();
  }
  HAL_TIM_MspPostInit(&htim8);

}

static void MX_TIM12_Init(void)
{

  TIM_OC_InitTypeDef sConfigOC = {0};

  htim12.Instance = TIM12;
  htim12.Init.Prescaler = 0;
  htim12.Init.CounterMode = TIM_COUNTERMODE_UP;
  htim12.Init.Period = 65535;
  htim12.Init.ClockDivision = TIM_CLOCKDIVISION_DIV1;
  htim12.Init.AutoReloadPreload = TIM_AUTORELOAD_PRELOAD_DISABLE;
  if (HAL_TIM_PWM_Init(&htim12) != HAL_OK)
  {
    Error_Handler();
  }
  sConfigOC.OCMode = TIM_OCMODE_PWM1;
  sConfigOC.Pulse = 0;
  sConfigOC.OCPolarity = TIM_OCPOLARITY_HIGH;
  sConfigOC.OCFastMode = TIM_OCFAST_DISABLE;
  if (HAL_TIM_PWM_ConfigChannel(&htim12, &sConfigOC, TIM_CHANNEL_1) != HAL_OK)
  {
    Error_Handler();
  }
  if (HAL_TIM_PWM_ConfigChannel(&htim12, &sConfigOC, TIM_CHANNEL_2) != HAL_OK)
  {
    Error_Handler();
  }
  HAL_TIM_MspPostInit(&htim12);

}

static void MX_UART4_Init(void)
{

  huart4.Instance = UART4;
  huart4.Init.BaudRate = 115200;
  huart4.Init.WordLength = UART_WORDLENGTH_8B;
  huart4.Init.StopBits = UART_STOPBITS_1;
  huart4.Init.Parity = UART_PARITY_NONE;
  huart4.Init.Mode = UART_MODE_TX_RX;
  huart4.Init.HwFlowCtl = UART_HWCONTROL_NONE;
  huart4.Init.OverSampling = UART_OVERSAMPLING_16;
  if (HAL_UART_Init(&huart4) != HAL_OK)
  {
    Error_Handler();
  }

}

static void MX_USART2_UART_Init(void)
{

  huart2.Instance = USART2;
  huart2.Init.BaudRate = 115200;
  huart2.Init.WordLength = UART_WORDLENGTH_8B;
  huart2.Init.StopBits = UART_STOPBITS_1;
  huart2.Init.Parity = UART_PARITY_NONE;
  huart2.Init.Mode = UART_MODE_TX_RX;
  huart2.Init.HwFlowCtl = UART_HWCONTROL_NONE;
  huart2.Init.OverSampling = UART_OVERSAMPLING_16;
  if (HAL_UART_Init(&huart2) != HAL_OK)
  {
    Error_Handler();
  }

}

static void MX_DMA_Init(void)
{

  /* DMA controller clock enable */
  __HAL_RCC_DMA1_CLK_ENABLE();
  __HAL_RCC_DMA2_CLK_ENABLE();

  /* DMA interrupt init */
  /* DMA1_Stream0_IRQn interrupt configuration */
  HAL_NVIC_SetPriority(DMA1_Stream0_IRQn, 0, 0);
  HAL_NVIC_EnableIRQ(DMA1_Stream0_IRQn);
  /* DMA1_Stream1_IRQn interrupt configuration */
  HAL_NVIC_SetPriority(DMA1_Stream1_IRQn, 0, 0);
  HAL_NVIC_EnableIRQ(DMA1_Stream1_IRQn);
  /* DMA1_Stream2_IRQn interrupt configuration */
  HAL_NVIC_SetPriority(DMA1_Stream2_IRQn, 0, 0);
  HAL_NVIC_EnableIRQ(DMA1_Stream2_IRQn);
  /* DMA1_Stream3_IRQn interrupt configuration */
  HAL_NVIC_SetPriority(DMA1_Stream3_IRQn, 0, 0);
  HAL_NVIC_EnableIRQ(DMA1_Stream3_IRQn);
  /* DMA1_Stream4_IRQn interrupt configuration */
  HAL_NVIC_SetPriority(DMA1_Stream4_IRQn, 0, 0);
  HAL_NVIC_EnableIRQ(DMA1_Stream4_IRQn);
  /* DMA1_Stream5_IRQn interrupt configuration */
  HAL_NVIC_SetPriority(DMA1_Stream5_IRQn, 0, 0);
  HAL_NVIC_EnableIRQ(DMA1_Stream5_IRQn);
  /* DMA1_Stream6_IRQn interrupt configuration */
  HAL_NVIC_SetPriority(DMA1_Stream6_IRQn, 0, 0);
  HAL_NVIC_EnableIRQ(DMA1_Stream6_IRQn);
  /* DMA1_Stream7_IRQn interrupt configuration */
  HAL_NVIC_SetPriority(DMA1_Stream7_IRQn, 0, 0);
  HAL_NVIC_EnableIRQ(DMA1_Stream7_IRQn);
  /* DMA2_Stream0_IRQn interrupt configuration */
  HAL_NVIC_SetPriority(DMA2_Stream0_IRQn, 0, 0);
  HAL_NVIC_EnableIRQ(DMA2_Stream0_IRQn);

}

static void MX_GPIO_Init(void)
{
  GPIO_InitTypeDef GPIO_InitStruct = {0};

  /* GPIO Ports Clock Enable */
  __HAL_RCC_GPIOC_CLK_ENABLE();
  __HAL_RCC_GPIOH_CLK_ENABLE();
  __HAL_RCC_GPIOA_CLK_ENABLE();
  __HAL_RCC_GPIOB_CLK_ENABLE();
  __HAL_RCC_GPIOD_CLK_ENABLE();

  /*Configure GPIO pin Output Level */
  HAL_GPIO_WritePin(GPIOC, LED3_Pin|LED2_Pin|LED1_Pin, GPIO_PIN_SET);

  /*Configure GPIO pin Output Level */
  HAL_GPIO_WritePin(SPI1_CS1_GPIO_Port, SPI1_CS1_Pin, GPIO_PIN_RESET);

  /*Configure GPIO pin Output Level */
  HAL_GPIO_WritePin(GPIOB, SPI1_CS2_Pin|SPI3_CS2_Pin, GPIO_PIN_RESET);

  /*Configure GPIO pin Output Level */
  HAL_GPIO_WritePin(SPI3_CS_GPIO_Port, SPI3_CS_Pin, GPIO_PIN_RESET);

  /*Configure GPIO pins : LED3_Pin LED2_Pin LED1_Pin */
  GPIO_InitStruct.Pin = LED3_Pin|LED2_Pin|LED1_Pin;
  GPIO_InitStruct.Mode = GPIO_MODE_OUTPUT_PP;
  GPIO_InitStruct.Pull = GPIO_NOPULL;
  GPIO_InitStruct.Speed = GPIO_SPEED_FREQ_LOW;
  HAL_GPIO_Init(GPIOC, &GPIO_InitStruct);

  /*Configure GPIO pin : SPI1_CS1_Pin */
  GPIO_InitStruct.Pin = SPI1_CS1_Pin;
  GPIO_InitStruct.Mode = GPIO_MODE_OUTPUT_PP;
  GPIO_InitStruct.Pull = GPIO_NOPULL;
  GPIO_InitStruct.Speed = GPIO_SPEED_FREQ_LOW;
  HAL_GPIO_Init(SPI1_CS1_GPIO_Port, &GPIO_InitStruct);

  /*Configure GPIO pins : BMI323_Int_2_Pin BMI323_Int_1_Pin */
  GPIO_InitStruct.Pin = BMI323_Int_2_Pin|BMI323_Int_1_Pin;
  GPIO_InitStruct.Mode = GPIO_MODE_IT_RISING;
  GPIO_InitStruct.Pull = GPIO_NOPULL;
  HAL_GPIO_Init(GPIOC, &GPIO_InitStruct);

  /*Configure GPIO pins : SPI1_CS2_Pin SPI3_CS2_Pin */
  GPIO_InitStruct.Pin = SPI1_CS2_Pin|SPI3_CS2_Pin;
  GPIO_InitStruct.Mode = GPIO_MODE_OUTPUT_PP;
  GPIO_InitStruct.Pull = GPIO_NOPULL;
  GPIO_InitStruct.Speed = GPIO_SPEED_FREQ_LOW;
  HAL_GPIO_Init(GPIOB, &GPIO_InitStruct);

  /*Configure GPIO pins : BNO086_Interrupt_Pin BNO086_WAKE_Pin */
  GPIO_InitStruct.Pin = BNO086_Interrupt_Pin|BNO086_WAKE_Pin;
  GPIO_InitStruct.Mode = GPIO_MODE_IT_RISING;
  GPIO_InitStruct.Pull = GPIO_NOPULL;
  HAL_GPIO_Init(GPIOA, &GPIO_InitStruct);

  /*Configure GPIO pin : SPI3_CS_Pin */
  GPIO_InitStruct.Pin = SPI3_CS_Pin;
  GPIO_InitStruct.Mode = GPIO_MODE_OUTPUT_PP;
  GPIO_InitStruct.Pull = GPIO_NOPULL;
  GPIO_InitStruct.Speed = GPIO_SPEED_FREQ_LOW;
  HAL_GPIO_Init(SPI3_CS_GPIO_Port, &GPIO_InitStruct);

}

void Error_Handler(void)
{
  __disable_irq();
  while (1)
  {
  }
}
